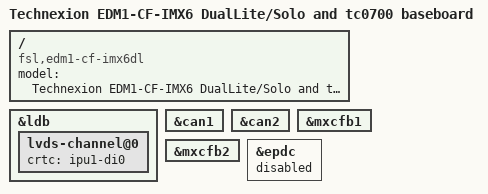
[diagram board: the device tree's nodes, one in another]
/*
 * Copyright 2016 Technexion Ltd.
 *
 * Author: Wig Cheng <wig.cheng@technexion.com>
 *	   Richard Hu <richard.hu@technexion.com>
 *	   Tapani Utriainen <tapani@technexion.com>
 *
 * This program is free software; you can redistribute it and/or modify
 * it under the terms of the GNU General Public License version 2 as
 * published by the Free Software Foundation.
 *
 */
/dts-v1/;

#include <dt-bindings/interrupt-controller/irq.h>
#include "imx6dl.dtsi"
#include "imx6qdl-edm1-cf.dtsi"
#include "baseboard_edm1_tc0700.dtsi"

/ {
	model = "Technexion EDM1-CF-IMX6 DualLite/Solo and tc0700 baseboard";
	compatible = "fsl,edm1-cf-imx6dl", "fsl,imx6dl";
};

&ldb {
	lvds-channel@0 {
		crtc = "ipu1-di0";
	};
};

&can1{
	status = "okay";
};

&can2{
	status = "okay";
};

&mxcfb1 {
	status = "okay";
};

&mxcfb2 {
	status = "okay";
};

#if 0
&mxcfb3 {
	status = "okay";
};

&mxcfb4 {
	status = "okay";
};
#endif

&epdc {
	status = "disabled";
};
